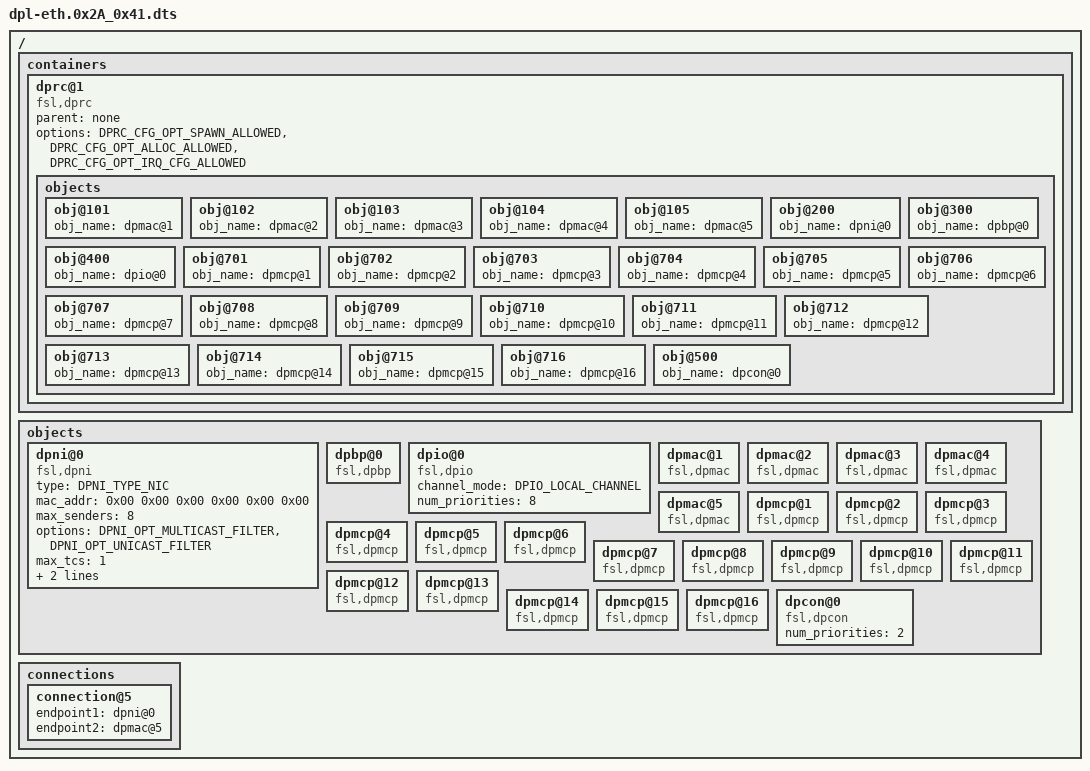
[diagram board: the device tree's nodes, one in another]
/*
 * Copyright 2015 Freescale Semiconductor, Inc.
 * "Bootstrap DPL" for ls2080a RDB boards featuring SerDes 0x2A_0x41.
 * This DPL defines one network interface mapped on the ETH0 copper port.
 * This together with the available DPMCP objects should be enough to boot Linux
 * and to allow the dynamic addition of other objects to the Linux container,
 * using the 'restool' utility.
 */

/dts-v1/;
/ {
	/*****************************************************************
         * Containers
         *****************************************************************/
	containers {
		dprc@1 {
			compatible = "fsl,dprc";
			parent = "none";
			options = "DPRC_CFG_OPT_SPAWN_ALLOWED" , "DPRC_CFG_OPT_ALLOC_ALLOWED", "DPRC_CFG_OPT_IRQ_CFG_ALLOWED";
			objects {
				/* ------------- MACs --------------*/
				obj@101 {
					obj_name = "dpmac@1";
				};
				obj@102 {
					obj_name = "dpmac@2";
				};
				obj@103 {
					obj_name = "dpmac@3";
				};
				obj@104 {
					obj_name = "dpmac@4";
				};
				obj@105 {
					obj_name = "dpmac@5";
				};

				/* ------------ DPNIs --------------*/
				obj@200 {
					obj_name = "dpni@0";
				};

				/* ------------ DPBPs --------------*/
				obj@300 {
					obj_name="dpbp@0";
				};

				/* ------------ DPIOs --------------*/
				obj@400 {
					obj_name = "dpio@0";
				};

				/* ------------ DPMCPs --------------*/
				obj@701 {
					obj_name="dpmcp@1";
				};
				obj@702 {
					obj_name="dpmcp@2";
				};
				obj@703 {
					obj_name="dpmcp@3";
				};
				obj@704 {
					obj_name="dpmcp@4";
				};
				obj@705 {
					obj_name="dpmcp@5";
				};
				obj@706 {
					obj_name="dpmcp@6";
				};
				obj@707 {
					obj_name="dpmcp@7";
				};
				obj@708 {
					obj_name="dpmcp@8";
				};
				obj@709 {
					obj_name="dpmcp@9";
				};
				obj@710 {
					obj_name="dpmcp@10";
				};
				obj@711 {
					obj_name="dpmcp@11";
				};
				obj@712 {
					obj_name="dpmcp@12";
				};
				obj@713 {
					obj_name="dpmcp@13";
				};
				obj@714 {
					obj_name="dpmcp@14";
				};
				obj@715 {
					obj_name="dpmcp@15";
				};
				obj@716 {
					obj_name="dpmcp@16";
				};

				/* ------------ DPCON --------------*/
				obj@500 {
					obj_name="dpcon@0";
				};
			};
		};
	};

	/*****************************************************************
         * Objects
         *****************************************************************/
	objects {

		/* ------------ DPNI --------------*/
		dpni@0 {
			compatible="fsl,dpni";
			type = "DPNI_TYPE_NIC";
			mac_addr = <0x00 0x00 0x00 0x00 0x00 0x00>;
			max_senders = <8>;
			options = "DPNI_OPT_MULTICAST_FILTER", "DPNI_OPT_UNICAST_FILTER";
			max_tcs = <1>;
			max_dist_per_tc = <0>;
			max_dist_key_size = <24>;
		};

		/* ------------ DPBP --------------*/
		dpbp@0 {
			compatible="fsl,dpbp";
		};

		/* ------------ DPIO --------------*/
		dpio@0 {
			compatible = "fsl,dpio";
			channel_mode = "DPIO_LOCAL_CHANNEL";
			num_priorities = <8>;
		};

		/* ------------ DPMAC --------------*/

		dpmac@1 {
			compatible = "fsl,dpmac";
		};
		dpmac@2 {
			compatible = "fsl,dpmac";
		};
		dpmac@3 {
			compatible = "fsl,dpmac";
		};
		dpmac@4 {
			compatible = "fsl,dpmac";
		};
		dpmac@5 {
			compatible = "fsl,dpmac";
		};

		/* ------------ DPMCP --------------*/
		dpmcp@1 {
			compatible="fsl,dpmcp";
		};
		dpmcp@2 {
			compatible="fsl,dpmcp";
		};
		dpmcp@3 {
			compatible="fsl,dpmcp";
		};
		dpmcp@4 {
			compatible="fsl,dpmcp";
		};
		dpmcp@5 {
			compatible="fsl,dpmcp";
		};
		dpmcp@6 {
			compatible="fsl,dpmcp";
		};
		dpmcp@7 {
			compatible="fsl,dpmcp";
		};
		dpmcp@8 {
			compatible="fsl,dpmcp";
		};
		dpmcp@9 {
			compatible="fsl,dpmcp";
		};
		dpmcp@10 {
			compatible="fsl,dpmcp";
		};
		dpmcp@11 {
			compatible="fsl,dpmcp";
		};
		dpmcp@12 {
			compatible="fsl,dpmcp";
		};
		dpmcp@13 {
			compatible="fsl,dpmcp";
		};
		dpmcp@14 {
			compatible="fsl,dpmcp";
		};
		dpmcp@15 {
			compatible="fsl,dpmcp";
		};
		dpmcp@16 {
			compatible="fsl,dpmcp";
		};

		/* ------------ DPCON --------------*/
		dpcon@0 {
			compatible="fsl,dpcon";
			num_priorities=<2>;
		};
	};

	/*****************************************************************
         * Connections
         *****************************************************************/
	connections {
		connection@5{
			/* First copper port (ETH0 on the RDB chassis) */
			endpoint1 = "dpni@0";
			endpoint2 = "dpmac@5";
		};
	};
};
